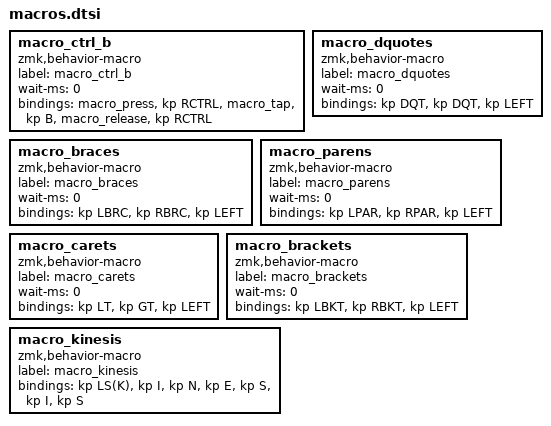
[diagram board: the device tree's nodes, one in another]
macro_ctrl_b: macro_ctrl_b{
compatible = "zmk,behavior-macro";
label = "macro_ctrl_b";
#binding-cells = <0>;
wait-ms = <0>;
bindings = <&macro_press &kp RCTRL>
	, <&macro_tap &kp B>
	, <&macro_release &kp RCTRL>
	;
};
macro_dquotes: macro_dquotes{
compatible = "zmk,behavior-macro";
label = "macro_dquotes";
#binding-cells = <0>;
wait-ms = <0>;
bindings = <&kp DQT>, <&kp DQT>, <&kp LEFT>;
};
macro_braces: macro_braces{
compatible = "zmk,behavior-macro";
label = "macro_braces";
#binding-cells = <0>;
wait-ms = <0>;
bindings = <&kp LBRC>, <&kp RBRC>, <&kp LEFT>;
};
macro_parens: macro_parens{
compatible = "zmk,behavior-macro";
label = "macro_parens";
#binding-cells = <0>;
wait-ms = <0>;
bindings = <&kp LPAR>, <&kp RPAR>, <&kp LEFT>;
};
macro_carets: macro_carets{
compatible = "zmk,behavior-macro";
label = "macro_carets";
#binding-cells = <0>;
wait-ms = <0>;
bindings = <&kp LT>, <&kp GT>, <&kp LEFT>;
};
macro_brackets: macro_brackets{
compatible = "zmk,behavior-macro";
label = "macro_brackets";
#binding-cells = <0>;
wait-ms = <0>;
bindings = <&kp LBKT>, <&kp RBKT>, <&kp LEFT>;
};
macro_kinesis: macro_kinesis{
compatible = "zmk,behavior-macro";
label = "macro_kinesis";
#binding-cells = <0>;
bindings = <&kp LS(K)>, <&kp I>, <&kp N>, <&kp E>, <&kp S>, <&kp I>, <&kp S>;
};
